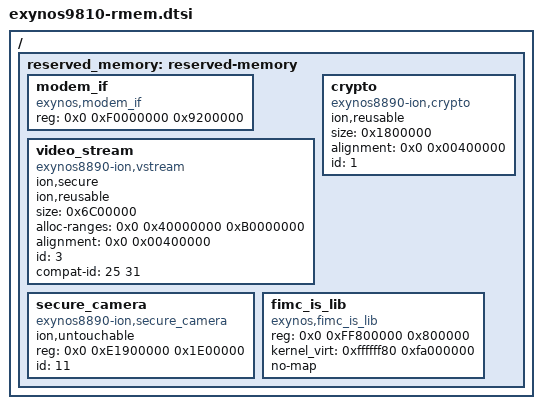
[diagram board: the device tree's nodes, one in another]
/*
 * SAMSUNG EXYNOS device tree source for reserved-memory
 *
 * Copyright (c) 2015 Samsung Electronics Co., Ltd.
 *		http://www.samsung.com
 *
 * This program is free software; you can redistribute it and/or modify
 * it under the terms of the GNU General Public License version 2 as
 * published by the Free Software Foundation.
 */

#include "../../../../../include/generated/autoconf.h"
#include <dt-bindings/soc/samsung/exynos-ss-table.h>

/ {
	reserved_memory: reserved-memory {
		#address-cells = <2>;
		#size-cells = <1>;
		ranges;

		modem_if {
			compatible = "exynos,modem_if";
			reg = <0x0 0xF0000000 0x9200000>;
		};

		video_stream {
			compatible = "exynos8890-ion,vstream";
			ion,secure;
			ion,reusable;
			size = <0x6C00000>;
			alloc-ranges = <0x0 0x40000000 0xB0000000>;
			alignment = <0x0 0x00400000>;
			id = <3>;
			compat-id = <25 31>;
		};

		crypto {
			compatible = "exynos8890-ion,crypto";
			ion,reusable;
			size = <0x1800000>;
			alignment = <0x0 0x00400000>;
			id = <1>;
		};

		secure_camera {
			compatible = "exynos8890-ion,secure_camera";
			ion,untouchable;
			reg = <0x0 0xE1900000 0x1E00000>;
			id = <11>;
		};

		fimc_is_lib {
			compatible = "exynos,fimc_is_lib";
			reg = <0x0 0xFF800000 0x800000>;
			kernel_virt = <0xffffff80 0xfa000000>;
			no-map;
		};
	};
};
